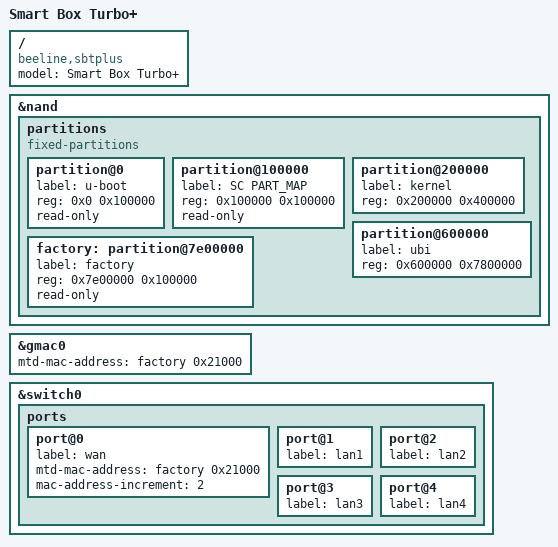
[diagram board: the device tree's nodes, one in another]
// SPDX-License-Identifier: GPL-2.0

#include "mt7621_beeline_sbtplus.dtsi"

/ {
	compatible = "beeline,sbtplus", "mediatek,mt7621-soc";
	model = "Smart Box Turbo+";
};

&nand {
	status = "okay";

	partitions {
		compatible = "fixed-partitions";
		#address-cells = <1>;
		#size-cells = <1>;

		partition@0 {
			label = "u-boot";
			reg = <0x0 0x100000>;
			read-only;
		};

		partition@100000 {
			label = "SC PART_MAP";
			reg = <0x100000 0x100000>;
			read-only;
		};

		partition@200000 {
			label = "kernel";
			reg = <0x200000 0x400000>;
		};

		partition@600000 {
			label = "ubi";
			reg = <0x600000 0x7800000>;
		};

		factory: partition@7e00000 {
			label = "factory";
			reg = <0x7e00000 0x100000>;
			read-only;
		};

	};
};

&gmac0 {
	mtd-mac-address = <&factory 0x21000>;
};

&switch0 {
	ports {
		port@0 {
			status = "okay";
			label = "wan";
			mtd-mac-address = <&factory 0x21000>;
			mac-address-increment = <2>;
		};

		port@1 {
			status = "okay";
			label = "lan1";
		};

		port@2 {
			status = "okay";
			label = "lan2";
		};

		port@3 {
			status = "okay";
			label = "lan3";
		};

		port@4 {
			status = "okay";
			label = "lan4";
		};

	};
};
